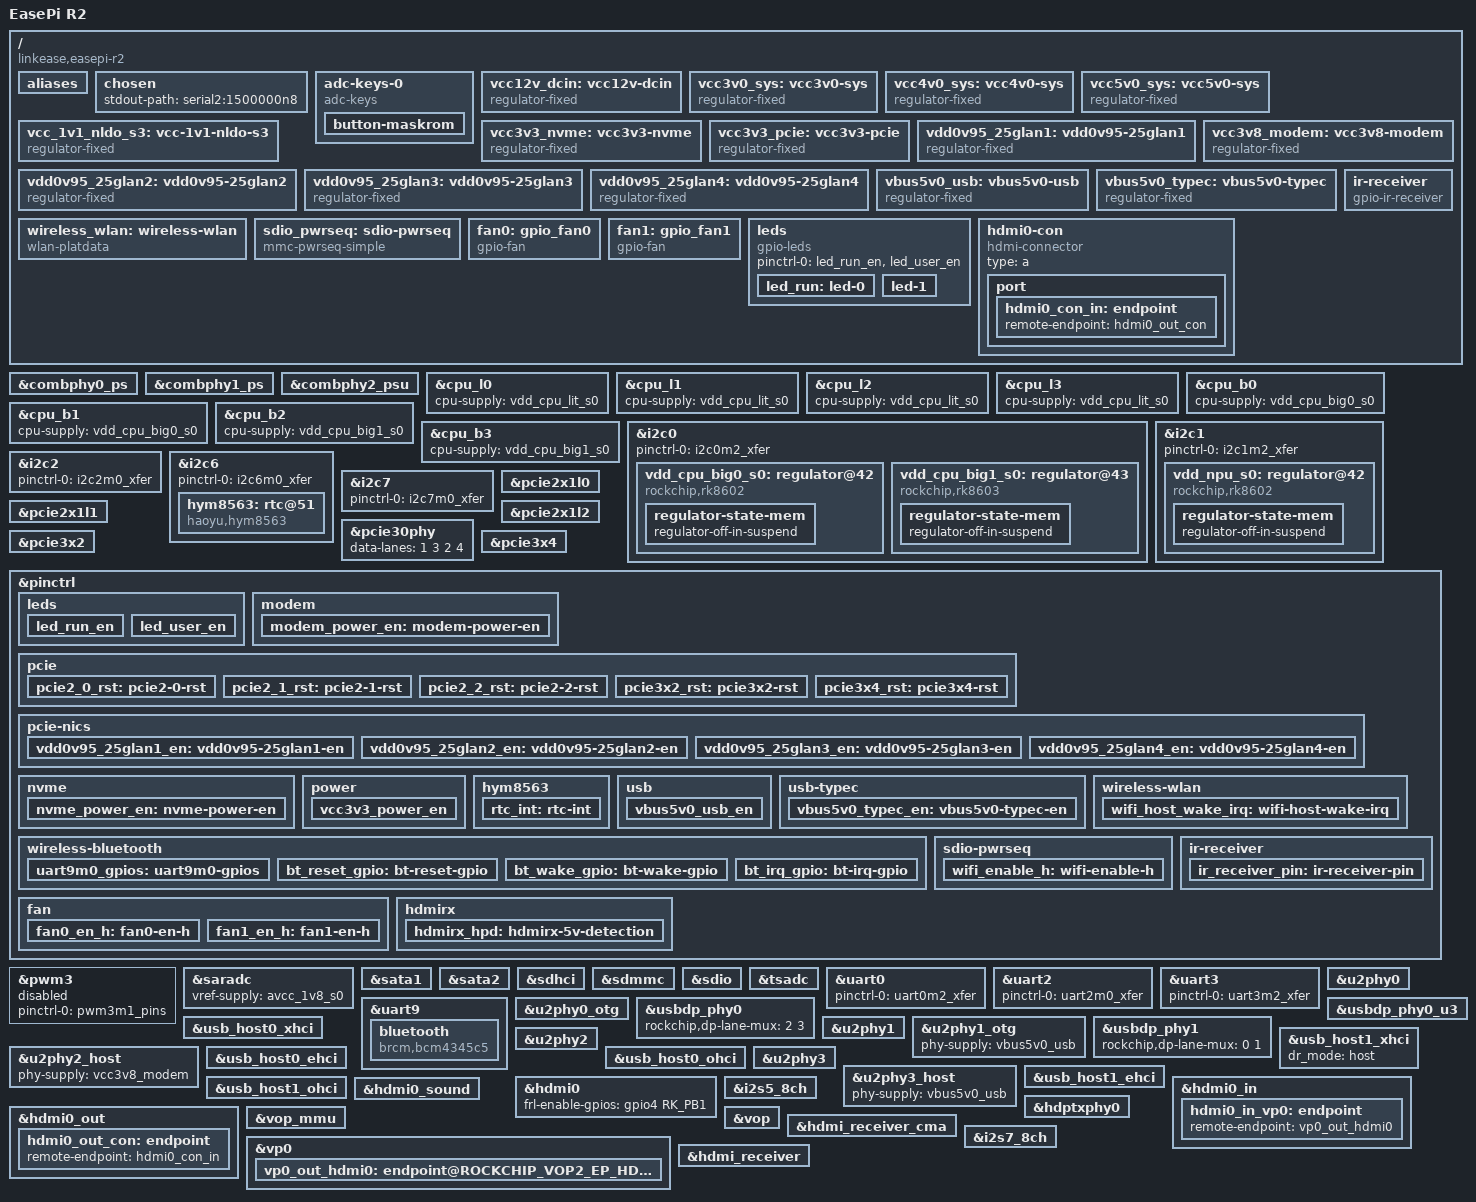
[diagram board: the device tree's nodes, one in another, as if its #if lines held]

/dts-v1/;

#include <dt-bindings/gpio/gpio.h>
#include <dt-bindings/input/input.h>
#include <dt-bindings/pinctrl/rockchip.h>
#include <dt-bindings/soc/rockchip,vop2.h>
#include <dt-bindings/usb/pd.h>
#include <rockchip/rk3588.dtsi>
#include "rk3588-rk806-single.dtsi"
#include "rk3588s-ip.dtsi"
#include "rk3588s-ip-supply.dtsi"
#include "rk3588-hdmirx.dtsi"

/ {
	model = "EasePi R2";
	compatible = "linkease,easepi-r2", "rockchip,rk3588";
	eth_order =  "0004:41:00.0,0002:21:00.0,0001:11:00.0,0003:31:00.0";

	aliases {
		led-boot = &led_run;
		led-failsafe = &led_run;
		led-running = &led_run;
		led-upgrade = &led_run;

		mmc0 = &sdmmc;
		mmc1 = &sdio;
		mmc2 = &sdhci;
	};

	chosen {
		stdout-path = "serial2:1500000n8";
	};

	adc-keys-0 {
		compatible = "adc-keys";
		io-channels = <&saradc 0>;
		io-channel-names = "buttons";
		keyup-threshold-microvolt = <1750000>;
		poll-interval = <100>;

		button-maskrom {
			label = "Mask Rom";
			linux,code = <KEY_RESTART>;
			press-threshold-microvolt = <878>;
		};
	};

	vcc12v_dcin: vcc12v-dcin {
		compatible = "regulator-fixed";
		regulator-always-on;
		regulator-boot-on;
		regulator-min-microvolt = <12000000>;
		regulator-max-microvolt = <12000000>;
		regulator-name = "vcc12v_dcin";
	};

	vcc3v0_sys: vcc3v0-sys {
		compatible = "regulator-fixed";
		regulator-always-on;
		regulator-boot-on;
		regulator-min-microvolt = <3000000>;
		regulator-max-microvolt = <3000000>;
		regulator-name = "vcc3v0_sys";
		vin-supply = <&vcc_3v3_s3>;
	};

	vcc4v0_sys: vcc4v0-sys {
		compatible = "regulator-fixed";
		regulator-always-on;
		regulator-boot-on;
		regulator-min-microvolt = <4000000>;
		regulator-max-microvolt = <4000000>;
		regulator-name = "vcc4v0_sys";
		vin-supply = <&vcc12v_dcin>;
	};

	vcc5v0_sys: vcc5v0-sys {
		compatible = "regulator-fixed";
		regulator-always-on;
		regulator-boot-on;
		regulator-min-microvolt = <5000000>;
		regulator-max-microvolt = <5000000>;
		regulator-name = "vcc5v0_sys";
		vin-supply = <&vcc12v_dcin>;
	};

	vcc_1v1_nldo_s3: vcc-1v1-nldo-s3 {
		compatible = "regulator-fixed";
		regulator-always-on;
		regulator-boot-on;
		regulator-min-microvolt = <1100000>;
		regulator-max-microvolt = <1100000>;
		regulator-name = "vcc_1v1_nldo_s3";
		vin-supply = <&vcc5v0_sys>;
	};

	vcc3v3_nvme: vcc3v3-nvme {
		compatible = "regulator-fixed";
		regulator-min-microvolt = <3300000>;
		regulator-max-microvolt = <3300000>;
		regulator-name = "vcc3v3_nvme";
		vin-supply = <&vcc12v_dcin>;
		enable-active-high;
		gpios = <&gpio3 RK_PD5 GPIO_ACTIVE_HIGH>;
		startup-delay-us = <5000>;
		pinctrl-names = "default";
		pinctrl-0 = <&nvme_power_en>;
	};

	vcc3v3_pcie: vcc3v3-pcie {
		compatible = "regulator-fixed";
		regulator-min-microvolt = <3300000>;
		regulator-max-microvolt = <3300000>;
		regulator-name = "vcc3v3_pcie";
		startup-delay-us = <50000>;
		vin-supply = <&vcc_3v3_s3>;
	};

	vdd0v95_25glan1: vdd0v95-25glan1 {
		compatible = "regulator-fixed";
		regulator-name = "vdd0v95_25glan1";
		regulator-min-microvolt = <950000>;
		regulator-max-microvolt = <950000>;
		regulator-always-on;
		regulator-boot-on;
		enable-active-high;
		gpios = <&gpio3 RK_PD0 GPIO_ACTIVE_HIGH>;
		pinctrl-names = "default";
		pinctrl-0 = <&vdd0v95_25glan1_en>;
		vin-supply = <&vcc_3v3_s3>;
	};
	vdd0v95_25glan2: vdd0v95-25glan2 {
		compatible = "regulator-fixed";
		regulator-name = "vdd0v95_25glan2";
		regulator-min-microvolt = <950000>;
		regulator-max-microvolt = <950000>;
		regulator-always-on;
		regulator-boot-on;
		enable-active-high;
		gpios = <&gpio4 RK_PB3 GPIO_ACTIVE_HIGH>;
		pinctrl-names = "default";
		pinctrl-0 = <&vdd0v95_25glan2_en>;
		vin-supply = <&vcc_3v3_s3>;
	};
	vdd0v95_25glan3: vdd0v95-25glan3 {
		compatible = "regulator-fixed";
		regulator-name = "vdd0v95_25glan3";
		regulator-min-microvolt = <950000>;
		regulator-max-microvolt = <950000>;
		regulator-always-on;
		regulator-boot-on;
		enable-active-high;
		gpios = <&gpio3 RK_PA4 GPIO_ACTIVE_HIGH>;
		pinctrl-names = "default";
		pinctrl-0 = <&vdd0v95_25glan3_en>;
		vin-supply = <&vcc_3v3_s3>;
	};
	vdd0v95_25glan4: vdd0v95-25glan4 {
		compatible = "regulator-fixed";
		regulator-name = "vdd0v95_25glan4";
		regulator-min-microvolt = <950000>;
		regulator-max-microvolt = <950000>;
		regulator-always-on;
		regulator-boot-on;
		enable-active-high;
		gpios = <&gpio3 RK_PC0 GPIO_ACTIVE_HIGH>;
		pinctrl-names = "default";
		pinctrl-0 = <&vdd0v95_25glan4_en>;
		vin-supply = <&vcc_3v3_s3>;
	};

	vcc3v8_modem: vcc3v8-modem {
		compatible = "regulator-fixed";
		enable-active-high;
		regulator-always-on;
		regulator-boot-on;
		gpios = <&gpio1 RK_PA0 GPIO_ACTIVE_HIGH>;
		regulator-min-microvolt = <3800000>;
		regulator-max-microvolt = <3800000>;
		regulator-name = "vcc3v8_modem";
		pinctrl-names = "default";
		pinctrl-0 = <&modem_power_en>;
		vin-supply = <&vcc12v_dcin>;
	};

	vbus5v0_usb: vbus5v0-usb {
		compatible = "regulator-fixed";
		enable-active-high;
		gpio = <&gpio4 RK_PB0 GPIO_ACTIVE_HIGH>;
		pinctrl-names = "default";
		pinctrl-0 = <&vbus5v0_usb_en>;
		regulator-min-microvolt = <5000000>;
		regulator-max-microvolt = <5000000>;
		regulator-name = "vbus5v0_usb";
		vin-supply = <&vcc5v0_sys>;
	};

#ifdef EASEPI_R2_OTG_USB3
	vbus5v0_typec: vbus5v0-typec {
		compatible = "regulator-fixed";
		enable-active-high;
		gpio = <&gpio3 RK_PA6 GPIO_ACTIVE_HIGH>;
		pinctrl-names = "default";
		pinctrl-0 = <&vbus5v0_typec_en>;
		regulator-min-microvolt = <5000000>;
		regulator-max-microvolt = <5000000>;
		regulator-name = "vbus5v0_typec";
		vin-supply = <&vcc5v0_sys>;
	};
#endif

/*
	wireless_bluetooth: wireless-bluetooth {
		compatible = "bluetooth-platdata";
		clocks = <&hym8563>;
		clock-names = "ext_clock";
		uart_rts_gpios = <&gpio4 RK_PC4 GPIO_ACTIVE_LOW>;// schematic wrongly connected to GPIO4_C3
		pinctrl-names = "default", "rts_gpio";
		pinctrl-0 = <&uart9m0_rtsn>, <&bt_reset_gpio>, <&bt_wake_gpio>, <&bt_irq_gpio>;
		pinctrl-1 = <&uart9m0_gpios>;
		BT,reset_gpio = <&gpio2 RK_PB4 GPIO_ACTIVE_HIGH>;
		BT,wake_gpio = <&gpio2 RK_PB6 GPIO_ACTIVE_HIGH>;
		BT,wake_host_irq = <&gpio0 RK_PA0 GPIO_ACTIVE_HIGH>;
	};
*/
	wireless_wlan: wireless-wlan {
		compatible = "wlan-platdata";
		wifi_chip_type = "ap6255";
		pinctrl-names = "default";
		pinctrl-0 = <&wifi_host_wake_irq>;
		WIFI,host_wake_irq = <&gpio0 RK_PB2 GPIO_ACTIVE_HIGH>;
	};

	sdio_pwrseq: sdio-pwrseq {
		compatible = "mmc-pwrseq-simple";
		clocks = <&hym8563>;
		clock-names = "ext_clock";
		pinctrl-names = "default";
		pinctrl-0 = <&wifi_enable_h>;
		post-power-on-delay-ms = <200>;
		reset-gpios = <&gpio2 RK_PB5 GPIO_ACTIVE_LOW>;
	};

	ir-receiver {
		compatible = "gpio-ir-receiver";
		gpios = <&gpio3 RK_PB2 GPIO_ACTIVE_LOW>;
		pinctrl-names = "default";
		pinctrl-0 = <&ir_receiver_pin>;
	};

	fan0: gpio_fan0 {
		compatible = "gpio-fan";
		fan-supply = <&vcc12v_dcin>;
		gpios = <&gpio3 RK_PC2 GPIO_ACTIVE_HIGH>;
		gpio-fan,speed-map =
				<   0 0>,
				<2500 1>;
		pinctrl-names = "default";
		pinctrl-0 = <&fan0_en_h>;
		#cooling-cells = <2>;
	};

	fan1: gpio_fan1 {
		compatible = "gpio-fan";
		fan-supply = <&vcc12v_dcin>;
		gpios = <&gpio3 RK_PC3 GPIO_ACTIVE_HIGH>;
		gpio-fan,speed-map =
				<   0 0>,
				<2500 1>;
		pinctrl-names = "default";
		pinctrl-0 = <&fan1_en_h>;
		#cooling-cells = <2>;
	};

	leds {
		compatible = "gpio-leds";
		pinctrl-names = "default";
		pinctrl-0 = <&led_run_en>, <&led_user_en>;

		led_run: led-0 {
			label = "green:run";
			linux,default-trigger = "heartbeat";
			gpios = <&gpio3 RK_PB7 GPIO_ACTIVE_HIGH>;
		};
		led-1 {
			label = "green:user";
			gpios = <&gpio3 RK_PB6 GPIO_ACTIVE_HIGH>;
		};
	};

	hdmi0-con {
		compatible = "hdmi-connector";
		type = "a";

		port {
			hdmi0_con_in: endpoint {
				remote-endpoint = <&hdmi0_out_con>;
			};
		};
	};
};

&combphy0_ps {
	status = "okay";
};

&combphy1_ps {
	status = "okay";
};

&combphy2_psu {
	status = "okay";
};

&cpu_l0 {
	cpu-supply = <&vdd_cpu_lit_s0>;
};

&cpu_l1 {
	cpu-supply = <&vdd_cpu_lit_s0>;
};

&cpu_l2 {
	cpu-supply = <&vdd_cpu_lit_s0>;
};

&cpu_l3 {
	cpu-supply = <&vdd_cpu_lit_s0>;
};

&cpu_b0 {
	cpu-supply = <&vdd_cpu_big0_s0>;
};

&cpu_b1 {
	cpu-supply = <&vdd_cpu_big0_s0>;
};

&cpu_b2 {
	cpu-supply = <&vdd_cpu_big1_s0>;
};

&cpu_b3 {
	cpu-supply = <&vdd_cpu_big1_s0>;
};

&i2c0 {
	pinctrl-names = "default";
	pinctrl-0 = <&i2c0m2_xfer>;
	status = "okay";

	vdd_cpu_big0_s0: regulator@42 {
		compatible = "rockchip,rk8602";
		reg = <0x42>;
		fcs,suspend-voltage-selector = <1>;
		regulator-name = "vdd_cpu_big0_s0";
		regulator-always-on;
		regulator-boot-on;
		regulator-min-microvolt = <550000>;
		regulator-max-microvolt = <1050000>;
		regulator-ramp-delay = <2300>;
		vin-supply = <&vcc4v0_sys>;

		regulator-state-mem {
			regulator-off-in-suspend;
		};
	};

	vdd_cpu_big1_s0: regulator@43 {
		compatible = "rockchip,rk8603", "rockchip,rk8602";
		reg = <0x43>;
		fcs,suspend-voltage-selector = <1>;
		regulator-name = "vdd_cpu_big1_s0";
		regulator-always-on;
		regulator-boot-on;
		regulator-min-microvolt = <550000>;
		regulator-max-microvolt = <1050000>;
		regulator-ramp-delay = <2300>;
		vin-supply = <&vcc4v0_sys>;

		regulator-state-mem {
			regulator-off-in-suspend;
		};
	};
};

&i2c1 {
	pinctrl-names = "default";
	pinctrl-0 = <&i2c1m2_xfer>;
	status = "okay";

	vdd_npu_s0: regulator@42 {
		compatible = "rockchip,rk8602";
		reg = <0x42>;
		fcs,suspend-voltage-selector = <1>;
		regulator-name = "vdd_npu_s0";
		regulator-always-on;
		regulator-boot-on;
		regulator-min-microvolt = <550000>;
		regulator-max-microvolt = <950000>;
		regulator-ramp-delay = <2300>;
		vin-supply = <&vcc4v0_sys>;

		regulator-state-mem {
			regulator-off-in-suspend;
		};
	};

};

&i2c2 {
	pinctrl-names = "default";
	pinctrl-0 = <&i2c2m0_xfer>;
	status = "okay";
};

&i2c6 {
	pinctrl-names = "default";
	pinctrl-0 = <&i2c6m0_xfer>;
	status = "okay";

	hym8563: rtc@51 {
		compatible = "haoyu,hym8563";
		reg = <0x51>;
		#clock-cells = <0>;
		clock-frequency = <32768>;
		clock-output-names = "hym8563";
		interrupt-parent = <&gpio0>;
		interrupts = <RK_PB0 IRQ_TYPE_LEVEL_LOW>;
		pinctrl-names = "default";
		pinctrl-0 = <&rtc_int>;
		wakeup-source;
	};
};

&i2c7 {
	pinctrl-names = "default";
	pinctrl-0 = <&i2c7m0_xfer>;
	status = "okay";
};

&pcie2x1l0 {
	// pcie30phy lane3, p0l1, 0002:20:00.0 => rtl8125 (lan1,eth1)
	pinctrl-names = "default";
	pinctrl-0 = <&pcie2_0_rst>;
	phys = <&pcie30phy>;
	reset-gpios = <&gpio4 RK_PA7 GPIO_ACTIVE_HIGH>;
	vpcie3v3-supply = <&vcc3v3_pcie>;
	status = "okay";
};

&pcie2x1l1 {
	// pcie30phy lane4, p1l1, 0003:30:00.0 => rtl8125 (lan3,eth3)
	pinctrl-names = "default";
	pinctrl-0 = <&pcie2_1_rst>;
	phys = <&pcie30phy>;
	reset-gpios = <&gpio3 RK_PC7 GPIO_ACTIVE_HIGH>;
	vpcie3v3-supply = <&vcc3v3_pcie>;
	status = "okay";
};

&pcie2x1l2 {
	// combphy0_ps, 0004:40:00.0 => rtl8125 (lan4,eth0)
	pinctrl-names = "default";
	pinctrl-0 = <&pcie2_2_rst>;
	reset-gpios = <&gpio3 RK_PC1 GPIO_ACTIVE_HIGH>;
	vpcie3v3-supply = <&vcc_3v3_s3>;
	status = "okay";
};

&pcie30phy {
	// divided into 4 lanes
	// rockchip,pcie30-phymode = <PHY_MODE_PCIE_NABIBI>;
	data-lanes = <1 3 2 4>;
	status = "okay";
};

&pcie3x2 {
	// pcie30phy lane2, p1l0, 0001:10:00.0 => rtl8125 (lan2,eth2)
	pinctrl-names = "default";
	pinctrl-0 = <&pcie3x2_rst>;
	num-lanes = <1>;
	reset-gpios = <&gpio0 RK_PC5 GPIO_ACTIVE_HIGH>;
	vpcie3v3-supply = <&vcc3v3_pcie>;
	status = "okay";
};

&pcie3x4 {
	// pcie30phy lane1, p0l0, 0000:00:00.0 => nvme
	pinctrl-names = "default";
	pinctrl-0 = <&pcie3x4_rst>;
	num-lanes = <1>;
	reset-gpios = <&gpio4 RK_PB6 GPIO_ACTIVE_HIGH>;
	vpcie3v3-supply = <&vcc3v3_nvme>;
	status = "okay";
};

&pinctrl {
	leds {
		led_run_en: led_run_en {
			rockchip,pins = <3 RK_PB7 RK_FUNC_GPIO &pcfg_pull_none>;
		};
		led_user_en: led_user_en {
			rockchip,pins = <3 RK_PB6 RK_FUNC_GPIO &pcfg_pull_none>;
		};
	};

	modem {
		modem_power_en: modem-power-en {
			rockchip,pins = <1 RK_PA0 RK_FUNC_GPIO &pcfg_pull_none>;
		};
	};
	pcie {
		pcie2_0_rst: pcie2-0-rst {
			rockchip,pins = <4 RK_PA7 RK_FUNC_GPIO &pcfg_pull_none>;
		};

		pcie2_1_rst: pcie2-1-rst {
			rockchip,pins = <3 RK_PC7 RK_FUNC_GPIO &pcfg_pull_none>;
		};

		pcie2_2_rst: pcie2-2-rst {
			rockchip,pins = <3 RK_PC1 RK_FUNC_GPIO &pcfg_pull_none>;
		};

		pcie3x2_rst: pcie3x2-rst {
			rockchip,pins = <0 RK_PC5 RK_FUNC_GPIO &pcfg_pull_none>;
		};

		pcie3x4_rst: pcie3x4-rst {
			rockchip,pins = <4 RK_PB6 RK_FUNC_GPIO &pcfg_pull_none>;
		};
	};
	pcie-nics {
		vdd0v95_25glan1_en: vdd0v95-25glan1-en {
			rockchip,pins = <3 RK_PD0 RK_FUNC_GPIO &pcfg_pull_none>;
		};
		vdd0v95_25glan2_en: vdd0v95-25glan2-en {
			rockchip,pins = <4 RK_PB3 RK_FUNC_GPIO &pcfg_pull_none>;
		};
		vdd0v95_25glan3_en: vdd0v95-25glan3-en {
			rockchip,pins = <3 RK_PA4 RK_FUNC_GPIO &pcfg_pull_none>;
		};
		vdd0v95_25glan4_en: vdd0v95-25glan4-en {
			rockchip,pins = <3 RK_PC0 RK_FUNC_GPIO &pcfg_pull_none>;
		};
	};
	nvme {
		nvme_power_en: nvme-power-en {
			rockchip,pins = <3 RK_PD5 RK_FUNC_GPIO &pcfg_pull_none>;
		};
	};
	power {
		vcc3v3_power_en: vcc3v3_power_en {
			rockchip,pins = <0 RK_PB7 RK_FUNC_GPIO &pcfg_pull_none>;
		};
	};
	hym8563 {
		rtc_int: rtc-int {
			rockchip,pins = <0 RK_PB0 RK_FUNC_GPIO &pcfg_pull_up>;
		};
	};
	usb {
		vbus5v0_usb_en: vbus5v0_usb_en {
			rockchip,pins = <4 RK_PB0 RK_FUNC_GPIO &pcfg_pull_none>;
		};

	};

	usb-typec {
		vbus5v0_typec_en: vbus5v0-typec-en {
			rockchip,pins = <3 RK_PA6 RK_FUNC_GPIO &pcfg_pull_none>;
		};
	};

	wireless-bluetooth {
		uart9m0_gpios: uart9m0-gpios {
			rockchip,pins = <4 RK_PC4 RK_FUNC_GPIO &pcfg_pull_none>;
		};

		bt_reset_gpio: bt-reset-gpio {
			rockchip,pins = <2 RK_PB4 RK_FUNC_GPIO &pcfg_pull_none>;
		};

		bt_wake_gpio: bt-wake-gpio {
			rockchip,pins = <2 RK_PB6 RK_FUNC_GPIO &pcfg_pull_none>;
		};

		bt_irq_gpio: bt-irq-gpio {
			rockchip,pins = <0 RK_PA0 RK_FUNC_GPIO &pcfg_pull_down>;
		};
	};
	wireless-wlan {
		wifi_host_wake_irq: wifi-host-wake-irq {
			rockchip,pins = <0 RK_PB2 RK_FUNC_GPIO &pcfg_pull_down>;
		};
	};
	sdio-pwrseq {
		wifi_enable_h: wifi-enable-h {
			rockchip,pins = <2 RK_PB5 RK_FUNC_GPIO &pcfg_pull_none>;
		};
	};
	ir-receiver {
		ir_receiver_pin: ir-receiver-pin {
			rockchip,pins = <3 RK_PB2 RK_FUNC_GPIO &pcfg_pull_none>;
		};
	};
	fan {
		fan0_en_h: fan0-en-h {
			rockchip,pins = <3 RK_PC2 RK_FUNC_GPIO &pcfg_pull_none>;
		};
		fan1_en_h: fan1-en-h {
			rockchip,pins = <3 RK_PC3 RK_FUNC_GPIO &pcfg_pull_none>;
		};
	};
	hdmirx {
		hdmirx_hpd: hdmirx-5v-detection {
			rockchip,pins = <1 RK_PD5 RK_FUNC_GPIO &pcfg_pull_up>;
		};
	};
};

&pwm3 {
	// IR, but use gpio
	status = "disabled";
	pinctrl-0 = <&pwm3m1_pins>;
};

&saradc {
	vref-supply = <&avcc_1v8_s0>;
	status = "okay";
};

&sata1 {
	status = "okay";
};

&sata2 {
	status = "okay";
};

// eMMC
&sdhci {
	bus-width = <8>;
	no-sdio;
	no-sd;
	non-removable;
	max-frequency = <200000000>;
	mmc-hs400-1_8v;
	mmc-hs400-enhanced-strobe;
	status = "okay";
};

// TF Card slot
&sdmmc {
	bus-width = <4>;
	cap-mmc-highspeed;
	cap-sd-highspeed;
	disable-wp;
	no-mmc;
	no-sdio;
	sd-uhs-sdr50;
	vmmc-supply = <&vcc_3v3_s3>;
	vqmmc-supply = <&vccio_sd_s0>;
	cd-gpios = <&gpio0 RK_PA4 GPIO_ACTIVE_LOW>;
	status = "okay";
};

// WiFi SDIO
&sdio {
	bus-width = <4>;
	cap-sd-highspeed;
	cap-sdio-irq;
	disable-wp;
	keep-power-in-suspend;
	max-frequency = <150000000>;
	mmc-pwrseq = <&sdio_pwrseq>;
	no-mmc;
	no-sd;
	non-removable;
	rockchip,default-sample-phase = <90>;
	sd-uhs-sdr50;
	sd-uhs-sdr104;
	supports-sdio;
	// vmmc-supply = <&vcc_1v8_s3>;
	// vqmmc-supply = <&vcc_1v8_s0>;
	pinctrl-names = "default";
	pinctrl-0 = <&sdiom0_pins>;
	status = "okay";
};

&tsadc {
	status = "okay";
};

&uart0 {
	pinctrl-0 = <&uart0m2_xfer>;
	status = "okay";
};

// debug uart
&uart2 {
	pinctrl-0 = <&uart2m0_xfer>;
	status = "okay";
};

&uart3 {
	pinctrl-0 = <&uart3m2_xfer>;
	status = "okay";
};

// bluetooth
&uart9 {
	pinctrl-0 = <&uart9m0_xfer &uart9m0_ctsn &uart9m0_rtsn>;
	status = "okay";
	uart-has-rtscts;
	bluetooth {
		compatible = "brcm,bcm4345c5";
		clocks = <&hym8563>;
		clock-names = "ext_clock";
		/*
		interrupt-parent = <&gpio0>;
		interrupts = <RK_PA0 IRQ_TYPE_LEVEL_LOW>;
		interrupt-names = "host-wakeup";
		*/
		host-wakeup-gpios = <&gpio0 RK_PA0 GPIO_ACTIVE_HIGH>;
		device-wakeup-gpios = <&gpio2 RK_PB6 GPIO_ACTIVE_HIGH>;
		shutdown-gpios = <&gpio2 RK_PB4 GPIO_ACTIVE_HIGH>;
		max-speed = <1500000>;
		pinctrl-names = "default";
		pinctrl-0 = <&bt_reset_gpio &bt_wake_gpio &bt_irq_gpio>;
		vbat-supply = <&vcc_3v3_s3>;
		vddio-supply = <&vcc_1v8_s3>;
	};
};

// type-c for firmware update
&u2phy0 {
	status = "okay";
};

&u2phy0_otg {
	rockchip,typec-vbus-det;
#ifdef EASEPI_R2_OTG_USB3
	vbus-supply = <&vbus5v0_typec>;
#endif
	status = "okay";
};

#ifdef EASEPI_R2_OTG_USB3
&usbdp_phy0 {
	rockchip,dp-lane-mux = <2 3>;
	status = "okay";
};

&usbdp_phy0_u3 {
	status = "okay";
};
#endif

&usb_host0_xhci {
	extcon = <&u2phy0>;
#ifdef EASEPI_R2_OTG_USB3
	dr_mode = "otg";
#else
	dr_mode = "peripheral";
	maximum-speed = "high-speed";
	phys = <&u2phy0_otg>;
	phy-names = "usb2-phy";
#endif
	status = "okay";
};

// usb 3.0
&u2phy1 {
	status = "okay";
};

&u2phy1_otg {
	phy-supply = <&vbus5v0_usb>;
	status = "okay";
};

&usbdp_phy1 {
	rockchip,dp-lane-mux = <0 1>;
	status = "okay";
};

&usb_host1_xhci {
	dr_mode = "host";
	status = "okay";
};

// 4G modem
&u2phy2 {
	status = "okay";
};

&u2phy2_host {
	phy-supply = <&vcc3v8_modem>;
	status = "okay";
};

&usb_host0_ehci {
	status = "okay";
};

&usb_host0_ohci {
	status = "okay";
};

// usb 2.0
&u2phy3 {
	status = "okay";
};

&u2phy3_host {
	phy-supply = <&vbus5v0_usb>;
	status = "okay";
};

&usb_host1_ehci {
	status = "okay";
};

&usb_host1_ohci {
	status = "okay";
};

// display
&hdmi0 {
	frl-enable-gpios = <&gpio4 RK_PB1 GPIO_ACTIVE_HIGH>;
	status = "okay";
};

&hdmi0_in {
	hdmi0_in_vp0: endpoint {
		remote-endpoint = <&vp0_out_hdmi0>;
	};
};

&hdmi0_out {
	hdmi0_out_con: endpoint {
		remote-endpoint = <&hdmi0_con_in>;
	};
};

&i2s5_8ch {
	status = "okay";
};

&hdmi0_sound {
	status = "okay";
};

&hdptxphy0 {
	status = "okay";
};

&vop_mmu {
	status = "okay";
};

&vop {
	status = "okay";
};

&vp0 {
	vp0_out_hdmi0: endpoint@ROCKCHIP_VOP2_EP_HDMI0 {
		reg = <ROCKCHIP_VOP2_EP_HDMI0>;
		remote-endpoint = <&hdmi0_in_vp0>;
	};
};

&hdmi_receiver_cma {
	status = "okay";
};

&i2s7_8ch {
	status = "okay";
};

&hdmi_receiver {
	hpd-gpios = <&gpio1 RK_PD5 GPIO_ACTIVE_LOW>;
	//hpd-is-active-low;
	pinctrl-0 = <&hdmim1_rx_cec &hdmim1_rx_hpdin &hdmim1_rx_scl &hdmim1_rx_sda &hdmirx_hpd>;
	pinctrl-names = "default";
	status = "okay";
};
